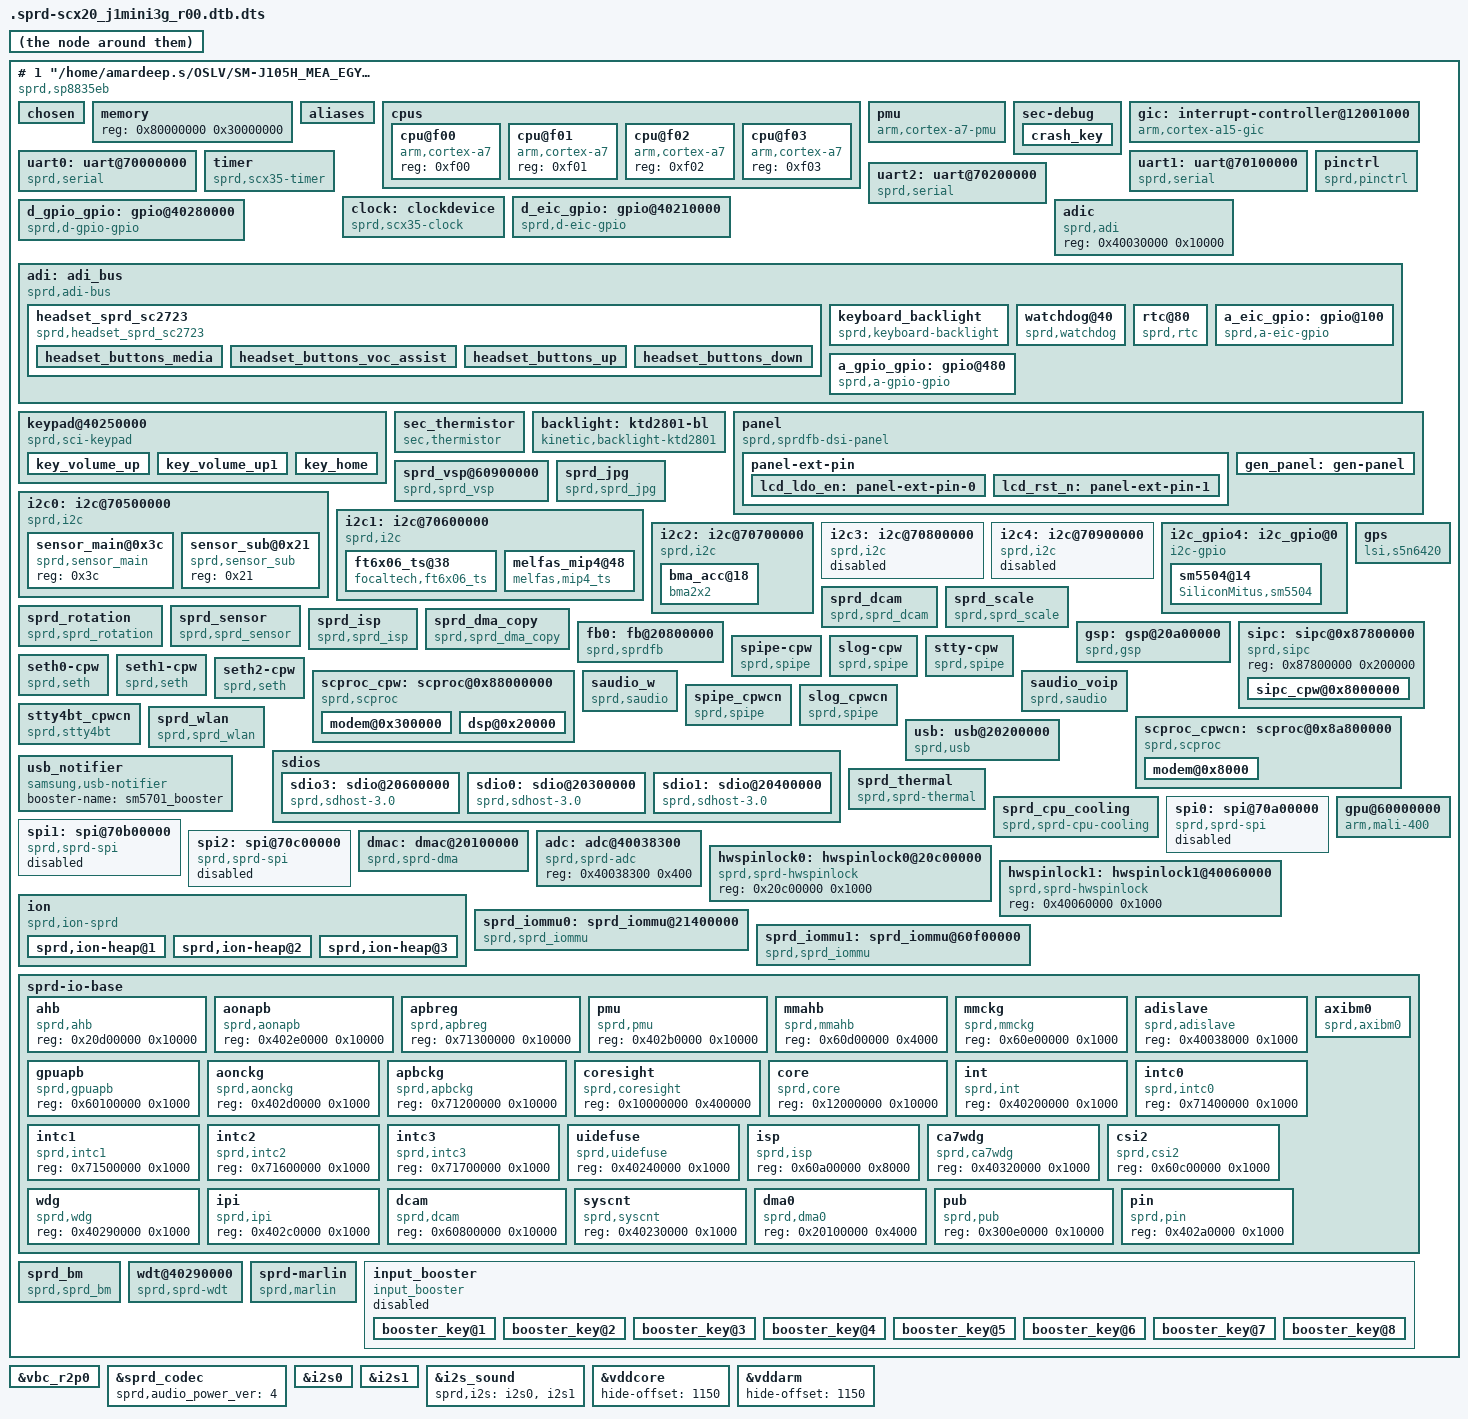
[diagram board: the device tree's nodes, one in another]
# 1 "arch/arm/boot/dts/sprd-scx20_j1mini3g_r00.dts"
# 1 "<command-line>"
# 1 "arch/arm/boot/dts/sprd-scx20_j1mini3g_r00.dts"
# 9 "arch/arm/boot/dts/sprd-scx20_j1mini3g_r00.dts"
/dts-v1/;


/memreserve/ 0x87800000 0x200000;


/memreserve/ 0x88000000 0x1c00000;


/memreserve/ 0x8a800000 0x201000;


/memreserve/ 0x9F8AD000 0x465000;


/memreserve/ 0x9FD12000 0x2EE000;

/include/ "skeleton.dtsi"
/include/ "scx20-clocks.dtsi"
/include/ "sc2723-regulators.dtsi"
/include/ "sprd-sound.dtsi"
/include/ "sprd-scx20_j1mini3g_battery_r00.dtsi"
# 1 "/home/amardeep.s/OSLV/SM-J105H_MEA_EGY/android/kernel/arch/arm/boot/dts/include/dt-bindings/gpio/gpio.h" 1
# 32 "arch/arm/boot/dts/sprd-scx20_j1mini3g_r00.dts" 2
# 1 "/home/amardeep.s/OSLV/SM-J105H_MEA_EGY/android/kernel/arch/arm/boot/dts/include/dt-bindings/interrupt-controller/irq.h" 1
# 33 "arch/arm/boot/dts/sprd-scx20_j1mini3g_r00.dts" 2
/ {
 model = "Spreadtrum SP8835EB board";
 compatible = "sprd,sp8835eb";
 sprd,sc-id = <8830 0 0x20000>;
 #address-cells = <1>;
 #size-cells = <1>;
 interrupt-parent = <&gic>;

 chosen {
  bootargs = "loglevel=0 init=/init root=/dev/ram0 rw";
  linux,initrd-start = <0x85500000>;
  linux,initrd-end = <0x855a3212>;
 };

 memory {
  device_type = "memory";
  reg = <0x80000000 0x30000000>;
 };

 aliases {
  serial0 = &uart0;
  serial1 = &uart1;
  serial2 = &uart2;
  i2c0 = &i2c0;
  i2c1 = &i2c1;
  i2c2 = &i2c2;

  i2c_gpio4 = &i2c_gpio4;
  lcd0 = &fb0;
  spi0 = &spi0;
  spi1 = &spi1;
  spi2 = &spi2;
  hwspinlock0 = &hwspinlock0;
  hwspinlock1 = &hwspinlock1;
 };

 cpus {
  #address-cells = <1>;
  #size-cells = <0>;

  cpu@f00 {
   device_type = "cpu";
   compatible = "arm,cortex-a7";
   reg = <0xf00>;
  };

  cpu@f01 {
   device_type = "cpu";
   compatible = "arm,cortex-a7";
   reg = <0xf01>;
  };

  cpu@f02 {
   device_type = "cpu";
   compatible = "arm,cortex-a7";
   reg = <0xf02>;
  };

  cpu@f03 {
   device_type = "cpu";
   compatible = "arm,cortex-a7";
   reg = <0xf03>;
  };
 };

        pmu {
                compatible = "arm,cortex-a7-pmu";
                interrupts = <0 92 0x0>,
    <0 93 0x0>,
    <0 94 0x0>,
    <0 95 0x0>;
        };

 sec-debug {
  crash_key {
   keys = "vol-down", "power", "power";
   size-keys = <3>;
   timeout = <1000>;
  };
 };

    gic: interrupt-controller@12001000 {
        compatible = "arm,cortex-a15-gic", "arm,cortex-a9-gic";
        #interrupt-cells = <3>;
        #address-cells = <0>;
        interrupt-controller;
        reg = <0x12001000 0x1000>,
              <0x12002000 0x1000>;
    };

 uart0: uart@70000000 {
  compatible = "sprd,serial";
  interrupts = <0 2 0x0>;
  reg = <0x70000000 0x1000>;
  clock-names = "clk_uart0";
  clocks = <&clock 60>;
  sprdclk = <48000000>;
  sprdwaketype = "BT_RTS_HIGH_WHEN_SLEEP";
 };
 uart1: uart@70100000 {
  compatible = "sprd,serial";
  interrupts = <0 3 0x0>;
  reg = <0x70100000 0x1000>;
  clock-names = "clk_uart1";
  clocks = <&clock 61>;
  sprdclk = <26000000>;
  sprdwaketype = "BT_RTS_HIGH_WHEN_SLEEP";
 };
 uart2: uart@70200000 {
  compatible = "sprd,serial";
  interrupts = <0 4 0x0>;
  reg = <0x70200000 0x1000>;
  clock-names = "clk_uart2";
  clocks = <&clock 62>;
  sprdclk = <26000000>;
  sprdwaketype = "BT_RTS_HIGH_WHEN_SLEEP";
 };

 timer {
  compatible = "sprd,scx35-timer";
  reg = <0x40230000 0x1000>,
   <0x40050000 0x1000>,
   <0x40220000 0x1000>,
   <0x40330000 0x1000>,
   <0x40340000 0x1000>;
  interrupts = <0 118 0x0>,
    <0 28 0x0>,
    <0 29 0x0>,
    <0 119 0x0>,
    <0 121 0x0>,
    <0 31 0x0>;
 };
 clock: clockdevice {
  compatible = "sprd,scx35-clock";
  #clock-cells = <1>;
 };
 d_eic_gpio: gpio@40210000{
         compatible = "sprd,d-eic-gpio";
         reg = <0x40210000 0x1000>;
         gpio-controller;
         interrupt-controller;
         #interrupt-cells = <2>;
         #gpio-cells = <2>;
         gpiobase = <288>;
         ngpios = <16>;
         interrupts = <0 37 0x0>;
 };
 d_gpio_gpio: gpio@40280000{
         compatible = "sprd,d-gpio-gpio";
         reg = <0x40280000 0x1000>;
         gpio-controller;
         interrupt-controller;
         #interrupt-cells = <2>;
         #gpio-cells = <2>;
         gpiobase = <0>;
         ngpios = <256>;
         interrupts = <0 35 0x0>;
 };
 pinctrl{
  compatible = "sprd,pinctrl";
  reg = <0x402a0000 0x1000>;
  pwr_domain = "vddsdio",
      "vddsim0",
      "vddsim1",
      "vddsim2",
      "vdd28";
  ctrl_desc = <0x10 16 1
        0x10 17 1
        0x10 18 1
        0x10 19 1
        0x10 20 1>;
 };
 adic:adic{
  compatible = "sprd,adi";
  reg = <0x40030000 0x10000>;
 };
 adi: adi_bus{
  compatible = "sprd,adi-bus";
  interrupts = <0 38 0x0>;
  reg = <0x40038000 0x1000>;
  interrupt-controller;
  sprd,irqnums = <11>;
  #interrupt-cells = <2>;
  #address-cells = <1>;
  #size-cells = <1>;
  ranges = <0X40 0x40038040 0x40>,
   <0x80 0x40038080 0x80>,
   <0x100 0x40038100 0x80>,
   <0x480 0x40038480 0x80>;


  headset_sprd_sc2723 {
   compatible = "sprd,headset_sprd_sc2723";
   gpio_switch = <0>;
   gpio_detect = <312>;
   gpio_button = <307>;
   irq_trigger_level_detect = <1>;
   irq_trigger_level_button = <1>;
   adc_threshold_gnd_average = <400>;
   adc_threshold_left_average = <500>;
   adc_threshold_3pole_detect = <3200>;
   adc_threshold_4pole_detect = <3201>;
   irq_threshold_buttont = <1>;
   voltage_headmicbias = <3000000>;
   nbuttons = <4>;
   headset_buttons_media {
    adc_min = <0>;
    adc_max = <490>;
    code = <226>;
    type = <0>;
   };
   headset_buttons_voc_assist {
    adc_min = <491>;
    adc_max = <685>;
    code = <0x246>;
    type = <0>;
   };
   headset_buttons_up {
    adc_min = <686>;
    adc_max = <1180>;
    code = <115>;
    type = <0>;
   };
   headset_buttons_down {
    adc_min = <1181>;
    adc_max =<3000>;
    code = <114>;
    type = <0>;
   };
  };

  keyboard_backlight {
   compatible = "sprd,keyboard-backlight";
  };
  watchdog@40{
   compatible = "sprd,watchdog";
   reg = <0X40 0x40>;
   interrupts = <3 0x0>;
  };
  rtc@80{
   compatible = "sprd,rtc";
   reg = <0X80 0x80>;
   interrupts = <2 0x0>;
  };
  a_eic_gpio: gpio@100{
   compatible = "sprd,a-eic-gpio";
   reg = <0X100 0x80>;
   gpio-controller;
   interrupt-controller;
   #interrupt-cells = <2>;
   #gpio-cells = <2>;
   gpiobase = <304>;
   ngpios = <16>;
   interrupt-parent = <&adi>;
   interrupts = <5 0x0>;
  };
  a_gpio_gpio: gpio@480{
   compatible = "sprd,a-gpio-gpio";
   reg = <0X480 0x80>;
   gpio-controller;
   interrupt-controller;
   #interrupt-cells = <2>;
   #gpio-cells = <2>;
   gpiobase = <256>;
   ngpios = <32>;
   interrupt-parent = <&adi>;
   interrupts = <1 0x0>;
  };
 };

 keypad@40250000{
  compatible = "sprd,sci-keypad";
  reg = <0x40250000 0x1000>;
  ngpios = <2>;
  gpios = <&a_eic_gpio 2 0>,<&a_eic_gpio 10 0>;
  interrupts = <0 36 0x0>;
  sprd,keypad-num-rows = <1>;
  sprd,keypad-num-columns = <3>;
  sprd,keypad-rows-choose-hw = <0x10000>;
  sprd,keypad-cols-choose-hw = <0x700>;
  sprd,debounce_time = <5000>;
  linux,keypad-no-autorepeat;
  sprd,support_long_key;

  key_volume_up {
   keypad,row = <0>;
   keypad,column = <0>;
   linux,code = <115>;
  };

  key_volume_up1 {
   keypad,row = <0>;
   keypad,column = <2>;
   linux,code = <115>;
  };

  key_home {
   keypad,row = <0>;
   keypad,column = <1>;
   linux,code = <172>;
  };
 };

 sec_thermistor {
  compatible = "sec,thermistor";
 };

 backlight: ktd2801-bl {
  compatible = "kinetic,backlight-ktd2801";
  backlight-name = "panel";
  backlight-brt-range = <
   0 0
   5 7
   5 7
   102 100
   255 215
  >;
  gen-panel-outdoor-mode-en;
  backlight-brt-outdoor = <
   255 255
  >;
  bl-ctrl = <&d_gpio_gpio 214 0>;
  backlight-on-delay = <110>;
 };

 panel {
  compatible = "sprd,sprdfb-dsi-panel";
  pinctrl-names = "default";
  gen-panel-backlight = <&backlight>;
  gen-panel = <&gen_panel>;
  interrupt-parent = <&d_gpio_gpio>;
  interrupts = <150 1>;
  gen-panel-esd-en;
  gen-panel-esd-gpio = <&d_gpio_gpio 150 0>;
  gen-panel-esd-type = <1>;
  panel-ext-pin {







   panel-ext-pin-on-0 = <
    &lcd_rst_n 0 10
    &lcd_ldo_en 1 5000
   >;
   panel-ext-pin-on = <
    &lcd_rst_n 1 10000
   >;
   panel-ext-pin-off = <
    &lcd_rst_n 0 10000
    &lcd_ldo_en 0 20000
   >;







    lcd_ldo_en: panel-ext-pin-0 {
    pin-name = "vddkpled";
    pin-type = <1>;
    pin-supply = <&vddkpled>;
   };
   lcd_rst_n: panel-ext-pin-1 {
    pin-name = "lcd_rst_n";
    pin-type = <0>;
    pin-gpio = <&d_gpio_gpio 103 0>;
   };
  };
  gen_panel: gen-panel {};
 };



 sprd_vsp@60900000{
  compatible = "sprd,sprd_vsp";
  reg = <0x60900000 0xc000>;
  interrupts = <0 43 0x0>;
  clock-names = "clk_mm_i", "clk_vsp", "clk_parent_0", "clk_parent_1", "clk_parent_2";
  clocks = <&clk_mm>, <&clk_vsp>, <&clk_192m>, <&clk_128m>, <&clk_76m8>;
  clock-parent-info = <2 3>;
  version = <4>;
 };
        sprd_jpg {
  compatible = "sprd,sprd_jpg";
  reg = <0x60b00000 0x8000>;
  interrupts = <0 42 0x0>;
  clock-names = "clk_mm_i","clk_jpg";
  clocks = <&clk_mm>, <&clk_jpg>;
 };


 i2c0: i2c@70500000 {
  compatible = "sprd,i2c";
  interrupts = <0 11 0x0>;
  reg = <0x70500000 0x1000>;
  #address-cells = <1>;
  #size-cells = <0>;
  sensor_main@0x3c{
   compatible = "sprd,sensor_main";
   reg = <0x3c>;
  };
  sensor_sub@0x21{
   compatible = "sprd,sensor_sub";
   reg = <0x21>;
  };
 };
 i2c1: i2c@70600000 {
  compatible = "sprd,i2c";
  interrupts = <0 12 0x0>;
  reg = <0x70600000 0x1000>;
  #address-cells = <1>;
  #size-cells = <0>;
  pull_up_mode = <1>;

  ft6x06_ts@38 {
   compatible = "focaltech,ft6x06_ts";
   reg = <0x38>;
   interrupt-parent = <&d_gpio_gpio>;
   interrupts = <232 0>;
   ft6x06,x_resolution = <479>;
   ft6x06,y_resolution = <799>;
  };

  melfas_mip4@48 {
              compatible = "melfas,mip4_ts";
              reg = <0x48>;
              mip4_ts,irq-gpio = <&d_gpio_gpio 232 0x00>;
              mip4_ts,max_x = <480>;
              mip4_ts,max_y = <800>;
              mip4_ts,x_num = <4>;
              mip4_ts,y_num = <7>;
              mip4_ts,key_flag;
   mip4_ts,fw_name = "melfas/j1mini3g.fw";
              mip4_ts,ext_fw_name = "/sdcard/j1mini3g.bin";
         };
  };

  i2c2: i2c@70700000 {
  compatible = "sprd,i2c";
  interrupts = <0 13 0x0>;
  reg = <0x70700000 0x1000>;
  #address-cells = <1>;
  #size-cells = <0>;

  bma_acc@18 {
   compatible = "bma2x2";
   reg = <0x18>;
   interrupt-parent = <&d_gpio_gpio>;
   interrupts = <238 0>;
   bma2x2,gpio_int1 = <&d_gpio_gpio 238 0x00>;
   bma2x2,accel_place = <6>;
  };
  };


  i2c3: i2c@70800000{
   compatible = "sprd,i2c";
   interrupts = <0 14 0x0>;
   reg = <0x70800000 0x1000>;
   #address-cells = <1>;
   #size-cells = <0>;
   status = "disabled";
  };

  i2c4: i2c@70900000{
  compatible = "sprd,i2c";
  interrupts = <0 15 0x0>;
  reg = <0x70900000 0x1000>;
  #address-cells = <1>;
  #size-cells = <0>;
  status = "disabled";
 };


 i2c_gpio4: i2c_gpio@0{
  compatible = "i2c-gpio";
  interrupts = <0 15 0x0>;
  reg = <0x70900000 0x1000>;
  #address-cells = <1>;
  #size-cells = <0>;
  gpios = <&d_gpio_gpio 82 0
   &d_gpio_gpio 81 0 >;
  i2c-gpio,delay-us = <10>;
  i2c-gpio,timeout-ms = <0>;

  sm5504@14 {
   compatible = "SiliconMitus,sm5504";
   reg = <0x14>;
   interrupt-parent = <&d_gpio_gpio>;
   sm5504,irq-gpio = <&d_gpio_gpio 233 0>;
  };
 };

 gps {
  compatible = "lsi,s5n6420";
  gps-pwr-en = <&d_gpio_gpio 237 0>;
  gps-reset = <&d_gpio_gpio 236 0>;
  gps-regulator = "vdd18";
  tcxo-regulator = "vddcammot";
  tcxo-regulator-volt = <3300000>;
 };

 sprd_dcam{
  compatible = "sprd,sprd_dcam";
  interrupts = <0 45 0>;
  reg = <0x60800000 0x100000>;
  clock-names = "clk_mm_i","clk_dcam";
  clocks = <&clk_mm>, <&clk_dcam>;
 };
 sprd_scale {
  compatible = "sprd,sprd_scale";
 };
 sprd_rotation {
  compatible = "sprd,sprd_rotation";
 };
 sprd_sensor {
  compatible = "sprd,sprd_sensor";
   reg = <0x60c00000 0x100000>;
  gpios = <&d_gpio_gpio 186 0
          &d_gpio_gpio 188 0
          &d_gpio_gpio 230 0
          &d_gpio_gpio 187 0
   &d_gpio_gpio 0 0
  &d_gpio_gpio 0 0
  &d_gpio_gpio 0 0
  &d_gpio_gpio 0 0
  &d_gpio_gpio 0 0
  &d_gpio_gpio 0 0
  &d_gpio_gpio 0 0
  &d_gpio_gpio 0 0
  &d_gpio_gpio 0 0>;
  vdds = "vddcammot",
   "vddcama",
   "vddcamd",
   "vddcamio",
   "vddcammot",
   "vddcama",
   "vddcamd",
   "vddcamio";
  clock-names ="clk_mm_i","clk_sensor","clk_ccir","clk_dcam","clk_dcam_mipi";
  clocks = <&clk_mm>, <&clk_sensor>,<&clk_ccir>, <&clk_dcam>, <&clk_dcam_mipi>;
 };
 sprd_isp {
  compatible = "sprd,sprd_isp";
  reg = <0x60a00000 0x100000>;
  clock-names = "clk_mm_i","clk_isp";
  clocks = <&clk_mm>, <&clk_isp>;
 };
 sprd_dma_copy {
  compatible = "sprd,sprd_dma_copy";
 };
 fb0: fb@20800000 {
  compatible = "sprd,sprdfb";
  reg = <0x20800000 0x1000>,<0x21800000 0x1000>;
  interrupts = <0 46 0x0>,<0 48 0x0>, <0 49 0x0>, <0 47 0x0>;
  clock-names = "dispc_clk_parent", "dispc_dbi_clk_parent", "dispc_dpi_clk_parent", "dispc_emc_clk_parent", "dispc_clk", "dispc_dbi_clk", "dispc_dpi_clk", "dispc_emc_clk", "fb_spi_clock", "fb_spi_clock_parent";
  clocks = <&clk_256m>, <&clk_256m>, <&clk_384m>, <&clk_aon_apb>, <&clk_dispc0>, <&clk_dispc0_dbi>, <&clk_dispc0_dpi>, <&clk_disp_emc>, <&clk_spi2>, <&ext_26m>;
  clock-src = <256000000 256000000 384000000>;
  dpi_clk_div = <16>;
  sprd,fb_use_reservemem;
  sprd,fb_mem = <0x9F8AD000 0x465000>;
 };
 gsp:gsp@20a00000 {
  compatible = "sprd,gsp";
  reg = <0x20a00000 0x1000>;
  interrupts = <0 51 0x0>;
  clock-names = "clk_gsp", "clk_gsp_emc", "clk_gsp_parent", "clk_aon_apb";
  clocks = <&clk_gsp>, <&clk_gsp_emc>, <&clk_256m>, <&clk_aon_apb>;
  gsp_mmu_ctrl_base = <0x21408000>;
 };

 sipc: sipc@0x87800000 {
  compatible = "sprd,sipc";
  reg = <0x87800000 0x200000>;

  #address-cells = <1>;
  #size-cells = <1>;
  ranges = <0x8000000 0x88000000 0x1c00000>,
   <0x07800000 0x87800000 0x140000>,
   <0x9bff000 0x89bff000 0x1000>,
   <0x0a800000 0x8a800000 0x201000>,
   <0x07940000 0x87940000 0xc0000>,
   <0x0aa00000 0x8aa00000 0x1000>;
  sipc_cpw@0x8000000 {
   sprd,name = "sipc-w";
   sprd,dst = <2>;
   sprd,ap2cp = <0x402c0000>;
   sprd,cp2ap = <0x402c0004>;
   sprd,trig = <0x01>;
   sprd,clr = <0x01>;
   interrupts = <0 68 0x0>;
   reg = <0x8000000 0x1c00000> ,
    <0x07800000 0x140000>,
    <0x9bff000 0x1000>;
  };
 };



 spipe-cpw {
  compatible = "sprd,spipe";
  sprd,name = "spipe_w";
  sprd,dst = <2>;
  sprd,channel = <4>;
  sprd,ringnr = <11>;
  sprd,size-rxbuf = <0x1000>;
  sprd,size-txbuf = <0x1000>;
 };

 slog-cpw {
  compatible = "sprd,spipe";
  sprd,name = "slog_w";
  sprd,dst = <2>;
  sprd,channel = <5>;
  sprd,ringnr = <1>;
  sprd,size-rxbuf = <0x40000>;
  sprd,size-txbuf = <0x8000>;
 };

 stty-cpw {
  compatible = "sprd,spipe";
  sprd,name = "stty_w";
  sprd,dst = <2>;
  sprd,channel = <6>;
  sprd,ringnr = <32>;
  sprd,size-rxbuf = <0x0800>;
  sprd,size-txbuf = <0x0800>;
 };

 seth0-cpw {
  compatible = "sprd,seth";
  sprd,name = "rmnet0";
  sprd,dst = <2>;
  sprd,channel = <7>;
  sprd,blknum = <64>;
 };

 seth1-cpw {
  compatible = "sprd,seth";
  sprd,name = "rmnet1";
  sprd,dst = <2>;
  sprd,channel = <8>;
  sprd,blknum = <64>;
 };

 seth2-cpw {
  compatible = "sprd,seth";
  sprd,name = "rmnet2";
  sprd,dst = <2>;
  sprd,channel = <9>;
  sprd,blknum = <64>;
 };

 scproc_cpw: scproc@0x88000000 {
  compatible = "sprd,scproc";
  sprd,name = "cpw";
  sprd,ctrl-reg = <0x44 0x44 0xb0 0xff>;
  sprd,ctrl-mask = <0x02000000 0x10000000 0x01 0xf0000>;
  sprd,iram-data = <0xe59f0000 0xe12fff10 0x88300000>;
  reg = <0x88000000 0x1c00000>,
   <0x50000000 0x0c>,
   <0x402b0000 0x10000>,
   <0x402b0000 0x10000>,
   <0x402b0000 0x10000>,
   <0x402b0000 0x10000>;
  interrupts = <0 83 0x0>;
  #address-cells = <1>;
  #size-cells = <1>;

  ranges = <0x300000 0x88300000 0x00800000>,
    <0x20000 0x88020000 0x00220000>;
  modem@0x300000 {
   cproc,name = "modem";
   reg = <0x300000 0x00800000>;
  };
  dsp@0x20000 {
   cproc,name = "dsp";
   reg = <0x20000 0x00220000>;
  };
 };

 saudio_w{
  compatible = "sprd,saudio";
  sprd,saudio-dst-id = <2>;
  sprd,ctrl_channel = <10>;
  sprd,playback_channel = <11>;
  sprd,capture_channel = <12>;
  sprd,monitor_channel = <13>;
  sprd,saudio-names = "VIRTUAL AUDIO W";
 };
 saudio_voip{
  compatible = "sprd,saudio";
  sprd,saudio-dst-id = <2>;
  sprd,ctrl_channel = <14>;
  sprd,playback_channel = <15>;
  sprd,capture_channel = <16>;
  sprd,monitor_channel = <17>;
  sprd,saudio-names = "saudiovoip";
 };



        spipe_cpwcn {
  compatible = "sprd,spipe";
  sprd,name = "spipe_wcn";
  sprd,dst = <3>;
  sprd,channel = <4>;
  sprd,ringnr = <12>;
  sprd,size-rxbuf = <0x1000>;
  sprd,size-txbuf = <0x1000>;
        };

 slog_cpwcn {
  compatible = "sprd,spipe";
  sprd,name = "slog_wcn";
  sprd,dst = <3>;
  sprd,channel = <5>;
  sprd,ringnr = <1>;
  sprd,size-rxbuf = <0x40000>;
  sprd,size-txbuf = <0x8000>;
 };

 stty4bt_cpwcn {
  compatible = "sprd,stty4bt";
  sprd,name = "sttybt";
  sprd,dst = <3>;
  sprd,channel = <4>;
  sprd,bufid = <10>;
 };

 scproc_cpwcn: scproc@0x8a800000 {
  compatible = "sprd,scproc";
  sprd,name = "cpwcn";
  sprd,ctrl-reg = <0x68 0x68 0xb0 0xb0>;
  sprd,ctrl-mask = <0x02000000 0x10000000 0x04 0x04>;
  sprd,iram-data = <0xe59f0000 0xe12fff10 0x8a808000>;
  reg = <0x8a800000 0x201000>,
   <0x50003000 0x1000>,
   <0x402b0000 0x10000>,
   <0x402b0000 0x10000>,
   <0x402b0000 0x10000>,
   <0x402b0000 0x10000>;
  interrupts = <0 85 0x0>;
  #address-cells = <1>;
  #size-cells = <1>;

  ranges = <0x8000 0x8a808000 0x201000>;
  modem@0x8000 {
   cproc,name = "modem";
   reg = <0x8000 0x201000>;
  };
 };

 sprd_wlan{
  compatible = "sprd,sprd_wlan";
 };

 sdios{
  #address-cells = <1>;
  #size-cells = <1>;
  ranges;
  sdio3: sdio@20600000{
   compatible = "sprd,sdhost-3.0";
   reg = <0x20600000 0x1000>;
   interrupts = <0 60 0x0>;
   sprd,name = "sdio_emmc";



   signal_default_Voltage = <1800000>;
   ocr_avail = <0x00040000>;
   clocks = <&clk_emmc>, <&clk_192m>;
   base_clk = <192000000>;
   caps = <0xC00F8D47>;
   caps2 = <0x202>;
   pm_caps = <0x4>;
   writeDelay = <0x1B>;
   readPosDelay = <0xC>;
   readNegDelay = <0xC>;
  };

  sdio0: sdio@20300000{
   compatible = "sprd,sdhost-3.0";
   reg = <0x20300000 0x1000>;
   interrupts = <0 57 0x0>;
   sprd,name = "sdio_sd";
   detect_gpio = <71>;
   SD_Pwr_Name = "vddsdcore";
   _1_8V_signal_Name = "vddsdio";
   signal_default_Voltage = <3000000>;
   ocr_avail = <0x00040000>;
   clocks = <&clk_sdio0>, <&clk_192m>;
   base_clk = <192000000>;
   caps = <0x40038407>;
   caps2 = <0x200>;
   pm_caps = <0x4>;
   writeDelay = <0x3>;
   readPosDelay = <0x3>;
   readNegDelay = <0x3>;
  };

  sdio1: sdio@20400000{
   compatible = "sprd,sdhost-3.0";
   reg = <0x20400000 0x1000>;
   interrupts = <0 58 0x0>;
   sprd,name = "sdio_wifi";




   ocr_avail = <0x00360080>;
   clocks = <&clk_sdio1>, <&clk_76m8>;
   base_clk = <96000000>;
   caps = <0xC00FA407>;
   caps2 = <0x0>;
   pm_caps = <0x5>;
   writeDelay = <0x03>;
   readPosDelay = <0x03>;
   readNegDelay = <0x03>;
  };
 };

 usb: usb@20200000{
  compatible = "sprd,usb";
  interrupts = <0 55 0x0>;
  ngpios = <2>;
  gpios = <&a_eic_gpio 0 0>, <&d_gpio_gpio 72 0>;
  reg = <0x20200000 0x1000>;
  tune_value = <0xd1a00020>;
  tune_ctrl1_value = <0x00001730>;
  usb-supply = <&vddusb>;
  #address-cells = <1>;
  #size-cells = <0>;
 };
 usb_notifier {
  compatible = "samsung,usb-notifier";
  booster-name = "sm5701_booster";
 };
 sprd_thermal {
  compatible = "sprd,sprd-thermal";
  id = <0>;
  interrupts = <0 26 0x0>;
  reg = <0x402f0000 0x1000>;
  trip_points_active = <65 69 95 110>;
  trip_points_lowoff = <0 57 61 80>;
  trip_points_critical = <110>;
  trip_num = <5>;
 };
 sprd_cpu_cooling{
  compatible = "sprd,sprd-cpu-cooling";
  id = <0>;
  max_freq = <1200000 1200000 813000 813000>;
  max_core = <4 4 4 1>;
  state_num = <4>;
 };

 spi0: spi@70a00000{
  compatible = "sprd,sprd-spi";
  interrupts = <0 7 0x0>;
  reg = <0x70a00000 0x1000>;
  clock-names = "clk_spi0";
  #address-cells = <1>;
  #size-cells = <0>;
  status = "disabled";
 };
 spi1: spi@70b00000{
  compatible = "sprd,sprd-spi";
  interrupts = <0 8 0x0>;
  reg = <0x70b00000 0x1000>;
  clock-names = "clk_spi1";
  #address-cells = <1>;
  #size-cells = <0>;
  status = "disabled";
 };
 spi2: spi@70c00000{
  compatible = "sprd,sprd-spi";
  interrupts = <0 9 0x0>;
  reg = <0x70c00000 0x1000>;
  clock-names = "clk_spi2";
  #address-cells = <1>;
  #size-cells = <0>;
  status = "disabled";
 };
 dmac: dmac@20100000{
  compatible = "sprd,sprd-dma";
  interrupts = <0 50 0x0>;
  reg = <0x20100000 0x4000>;
 };
 adc: adc@40038300{
  compatible = "sprd,sprd-adc";
  reg = <0x40038300 0x400>;
 };
 hwspinlock0: hwspinlock0@20c00000{
  compatible = "sprd,sprd-hwspinlock";
  reg = <0x20c00000 0x1000>;
 };
 hwspinlock1: hwspinlock1@40060000{
  compatible = "sprd,sprd-hwspinlock";
  reg = <0x40060000 0x1000>;
 };
 gpu@60000000 {
  compatible = "arm,mali-400", "arm,mali-utgard";
  reg = <0x60000000 0x10000>;
  interrupts = <0 39 0>, <0 39 0>, <0 39 0>, <0 39 0>, <0 39 0>;
  interrupt-names = "IRQGP", "IRQGPMMU", "IRQPP0", "IRQPPMMU0", "IRQPMU";

  pmu_domain_config = <0x1000 0x1000 0x0 0x0 0x0 0x0 0x0 0x0 0x0 0x1000 0x0 0x0>;
  pmu_switch_delay = <0xffff>;

  clocks = <&clk_gpu_axi>,<&clk_gpu>,<&clk_153m6>,<&clk_208m>,<&clk_256m>,<&clk_312m>,<&clk_384m>,<&clk_460m8>,<&clk_512m>;
  clock-names = "clk_gpu_axi","clk_gpu","clk_153m6","clk_208m","clk_256m","clk_312m","clk_384m","clk_460m8","clk_512m";

  freq-list-len = <4>;
  freq-lists = <153600 2 1>, <256000 4 1>, <384000 6 1>, <512000 8 1>;
  freq-default = <1>;
  freq-9 = <2>;
  freq-8 = <1>;
  freq-7 = <0>;
  freq-5 = <0>;
  freq-range-max = <3>;
  freq-range-min = <0>;
 };
 ion {
  compatible = "sprd,ion-sprd";
  #address-cells = <1>;
  #size-cells = <0>;

  sprd,ion-heap@1 {
   reg = <1>;
   reg-names = "ion_heap_system";
   sprd,ion-heap-type = <0>;
   sprd,ion-heap-mem = <0x0 0x0>;
  };

  sprd,ion-heap@2 {
   reg = <2>;
   reg-names = "ion_heap_carveout_mm";
   sprd,ion-heap-type = <0>;
   sprd,ion-heap-mem = <0x98800000 0x7100000>;
  };

  sprd,ion-heap@3 {
   reg = <3>;
   reg-names = "ion_heap_carveout_overlay";
   sprd,ion-heap-type = <2>;
   sprd,ion-heap-mem = <0x9FD12000 0x2EE000>;
  };
 };
 sprd_iommu0:sprd_iommu@21400000 {
  compatible = "sprd,sprd_iommu";
  func-name = "sprd_iommu_gsp";
  reg = <0x10000000 0x2000000>,
   <0x21400000 0x8000>,
   <0x21408000 0x8000>;
  reg_name = "iova","pgt","ctrl_reg";
  clock-names = "clk_gsp_emc","clk_153m6","clk_gsp";
  clocks = <&clk_gsp_emc>, <&clk_153m6>,<&clk_gsp>;
  status = "ok";
 };
 sprd_iommu1:sprd_iommu@60f00000 {
  compatible = "sprd,sprd_iommu";
  func-name = "sprd_iommu_mm";
  reg = <0x20000000 0x8000000>,
   <0x60f00000 0x20000>,
   <0x60f20000 0x2000>;
  reg_name = "iova","pgt","ctrl_reg";
  clock-names = "clk_mmu","clk_mm_i";
  clocks = <&clk_mmu>,<&clk_mm>;
  status = "ok";
 };

 sprd-io-base {
  #address-cells = <1>;
  #size-cells = <1>;
  ranges = <0 0 0x80000000>;
  ahb {
   compatible = "sprd,ahb";
   reg = <0x20d00000 0x10000>;
  };
  aonapb {
   compatible = "sprd,aonapb";
   reg = <0x402e0000 0x10000>;
  };
  apbreg {
   compatible = "sprd,apbreg";
   reg = <0x71300000 0x10000>;
  };
  pmu {
   compatible = "sprd,pmu";
   reg = <0x402b0000 0x10000>;
  };
  mmahb {
   compatible = "sprd,mmahb";
   reg = <0x60d00000 0x4000>;
  };
  mmckg {
   compatible = "sprd,mmckg";
   reg = <0x60e00000 0x1000>;
  };
  adislave {
   compatible = "sprd,adislave";
   reg = <0x40038000 0x1000>;
  };
  gpuapb {
   compatible = "sprd,gpuapb";
   reg = <0x60100000 0x1000>;
  };
  aonckg {
   compatible = "sprd,aonckg";
   reg = <0x402d0000 0x1000>;
  };
  apbckg {
   compatible = "sprd,apbckg";
   reg = <0x71200000 0x10000>;
  };
  coresight {
   compatible = "sprd,coresight";
   reg = <0x10000000 0x400000>;
  };
  core {
   compatible = "sprd,core";
   reg = <0x12000000 0x10000>;
  };
  int {
   compatible = "sprd,int";
   reg = <0x40200000 0x1000>;
  };
  intc0 {
   compatible = "sprd,intc0";
   reg = <0x71400000 0x1000>;
  };
  intc1 {
   compatible = "sprd,intc1";
   reg = <0x71500000 0x1000>;
  };
  intc2 {
   compatible = "sprd,intc2";
   reg = <0x71600000 0x1000>;
  };
  intc3 {
   compatible = "sprd,intc3";
   reg = <0x71700000 0x1000>;
  };
  uidefuse {
   compatible = "sprd,uidefuse";
   reg = <0x40240000 0x1000>;
  };
  isp {
   compatible = "sprd,isp";
   reg = <0x60a00000 0x8000>;
  };
  ca7wdg {
   compatible = "sprd,ca7wdg";
   reg = <0x40320000 0x1000>;
  };
  csi2 {
   compatible = "sprd,csi2";
   reg = <0x60c00000 0x1000>;
  };
  wdg {
   compatible = "sprd,wdg";
   reg = <0x40290000 0x1000>;
  };
  ipi {
   compatible = "sprd,ipi";
   reg = <0x402c0000 0x1000>;
  };
  dcam {
   compatible = "sprd,dcam";
   reg = <0x60800000 0x10000>;
  };
  syscnt {
   compatible = "sprd,syscnt";
   reg = <0x40230000 0x1000>;
  };
  dma0 {
   compatible = "sprd,dma0";
   reg = <0x20100000 0x4000>;
  };
  pub {
   compatible = "sprd,pub";
   reg = <0x300e0000 0x10000>;
  };
  pin {
   compatible = "sprd,pin";
   reg = <0x402a0000 0x1000>;
  };
  axibm0 {
   compatible = "sprd,axibm0";
   reg = <0 0x30040000 0 0x20000>;
   interrupts = <0 86 0x0>;
  };
 };
 sprd_bm {
  compatible = "sprd,sprd_bm";
  reg = <0x30040000 0xA0000>,
     <0x20E00000 0x300000>;
  interrupts = <0 86 0x0>;
  sprd,bm_status = <1>;
  sprd,bm_count = <10 10>;
  sprd,mm_chn = <0 1>;
  sprd,gpu_chn = <1 1>;
  sprd,disp_chn = <2 1>;
  sprd,cpu_chn = <3 1>;
  sprd,cp0_arm1_chn = <4 1>;
  sprd,cp0_arm0_chn = <5 1>;
  sprd,ap_chn = <6 1>;
  sprd,zip_chn = <7 1>;
  sprd,cp2_chn = <8 1>;
  sprd,cp0_dsp_chn = <9 1>;
  sprd,ap_cpu_chn = <0 0>;
  sprd,ap_dap_chn = <0 1>;
  sprd,ap_dma_w_chn = <1 0>;
  sprd,ap_dma_r_chn = <1 1>;
  sprd,ap_sdio_0_chn = <1 2>;
  sprd,ap_sdio_1_chn = <1 3>;
  sprd,ap_emmc_chn = <2 0>;
  sprd,ap_sdio_2_chn = <2 1>;
  sprd,ap_nfc_chn = <2 2>;
  sprd,ap_usb_chn = <2 3>;
 };
 wdt@40290000 {
  compatible = "sprd,sprd-wdt";
  reg = <0x40290000 0x1000>,
   <0x40320000 0x1000>;
  interrupts = <0 124 0x0>;
 };

 sprd-marlin {
  compatible = "sprd,marlin";
  gpios = <&d_gpio_gpio 59 0
   &d_gpio_gpio 58 0
   &d_gpio_gpio 57 0
   &d_gpio_gpio 47 0
   &d_gpio_gpio 56 0>;
   cp-rfctl-offset = <0xd8>;
  vdd-download = "vddcon";
  vdd-pa = "vddwifipa";
  clk-name = "clk_aux0";
  sdhci-name = "sdio_wifi";
 };

 input_booster {
  status = "disabled";
  compatible = "input_booster";
  #address-cells = <1>;
  #size-cells = <0>;

  booster_key@1 {
   input_booster,label = "KEY";
   input_booster,type = <0>;

   input_booster,levels = <1>;



   input_booster,cpu_freqs = <1200000>;
   input_booster,core_num_lock = <2>;


   input_booster,head_times = <200>;
   input_booster,tail_times = <0>;

  };
  booster_key@2 {
   input_booster,label = "TOUCHKEY";
   input_booster,type = <1>;

   input_booster,levels = <1>;



   input_booster,cpu_freqs = <768000>;
   input_booster,core_num_lock = <2>;


   input_booster,head_times = <0>;
   input_booster,tail_times = <300>;
  };
  booster_key@3 {
   input_booster,label = "TOUCH";
   input_booster,type = <2>;

   input_booster,levels = <1 2 3>;



   input_booster,cpu_freqs = <1200000 1200000 768000>;
   input_booster,core_num_lock = <2>;


   input_booster,head_times = <200 200 0>;
   input_booster,tail_times = <0 0 300>;
  };
  booster_key@4 {
   input_booster,label = "MULTITOUCH";
   input_booster,type = <3>;

   input_booster,levels = <1 2>;



   input_booster,cpu_freqs = <1200000 1200000>;
   input_booster,core_num_lock = <2>;


   input_booster,head_times = <1000 0>;
   input_booster,tail_times = <0 500>;
  };
  booster_key@5 {
   input_booster,label = "KEYBOARD";
   input_booster,type = <4>;

   input_booster,levels = <1 2>;



   input_booster,cpu_freqs = <1200000 1200000>;
   input_booster,core_num_lock = <2>;


   input_booster,head_times = <200 200>;
   input_booster,tail_times = <0 0>;
  };
  booster_key@6 {
   input_booster,label = "MOUSE";
   input_booster,type = <5>;

   input_booster,levels = <1 2>;



   input_booster,cpu_freqs = <1200000 768000>;
   input_booster,core_num_lock = <2>;


   input_booster,head_times = <200 0>;
   input_booster,tail_times = <0 300>;
  };
  booster_key@7 {
   input_booster,label = "MOUSE WHEEL";
   input_booster,type = <6>;

   input_booster,levels = <1 2>;



   input_booster,cpu_freqs = <1200000 0>;
   input_booster,core_num_lock = <2>;


   input_booster,head_times = <200 0>;
   input_booster,tail_times = <0 0>;
  };
  booster_key@8 {
   input_booster,label = "PEN HOVER";
   input_booster,type = <7>;

   input_booster,levels = <1 2>;



   input_booster,cpu_freqs = <1200000 768000>;
   input_booster,core_num_lock = <2>;


   input_booster,head_times = <200 0>;
   input_booster,tail_times = <0 300>;
  };
 };
};

&vbc_r2p0 {
 status = "okay";
};

&sprd_codec {
 status = "okay";
 sprd,audio_power_ver = <4>;
};

&i2s0 {
 sprd,config_type = "pcm";
 sprd,slave_timeout = <0xF11>;
 sprd,_hw_port = <0>;
 sprd,fs = <8000>;
 sprd,bus_type = <1>;
 sprd,rtx_mode = <3>;
 sprd,byte_per_chan = <1>;
 sprd,slave_mode = <0>;
 sprd,lsb = <1>;
 sprd,lrck = <1>;
 sprd,low_for_left = <1>;
 sprd,clk_inv = <0>;
 sprd,pcm_short_frame = <1>;
 sprd,pcm_slot = <0x1>;
 sprd,pcm_cycle = <1>;
 sprd,tx_watermark = <12>;
 sprd,rx_watermark = <20>;
 status = "okay";
};

&i2s1 {
 status = "okay";
};

&i2s_sound {
 sprd,i2s = <&i2s0>, <&i2s1>;
};

&vddcore{
 hide-offset = <1150>;
};
&vddarm{
 hide-offset = <1150>;
};
/include/ "sprd-dsi-panel-dsi_s6d77a1a01_j1mini3g_video.dtsi"
/include/ "sprd-dsi-panel-dsi_hx8369b_j1mini3g_video.dtsi"
/include/ "sprd-dsi-panel-dsi_sc7798d_j1minilte_video.dtsi"
